# nrf7140_sysctrl register map
Vendor: Nordic Semiconductor; Series: nRF71; File version: 1
Registers are 32-bit, read-write, reset 0x0 unless marked. A register's access mark holds for its fields unless they carry their own. Offsets are from the block's base; [hi:lo] are bit positions; lines under a group give offsets from that group; 'fields as' and 'values as' point back to an identical list.

## VDETPOF5V0 — VDETPOF5V0 peripheral 0
Base 0x5F979000
Same registers: VDETPOFVBAT 0x5F97A000
0x00 TASKS_PWRUP wo — Power up voltage detector
  [0] TASKS_PWRUP
    1=Trigger task
0x04 TASKS_PWRDOWN wo — Power down voltage detector
  [0] TASKS_PWRDOWN
    1=Trigger task
0x100 EVENTS_READY — Power up done
  [0] EVENTS_READY
    0=NotGenerated (Event not generated); 1=Generated (Event generated)
0x104 EVENTS_SETTLED — Settled flag for MODE handshake
  [0] EVENTS_SETTLED
    values as EVENTS_READY.EVENTS_READY
0x108 EVENTS_POFWARN — Power failure warning
  [0] EVENTS_POFWARN
    values as EVENTS_READY.EVENTS_READY
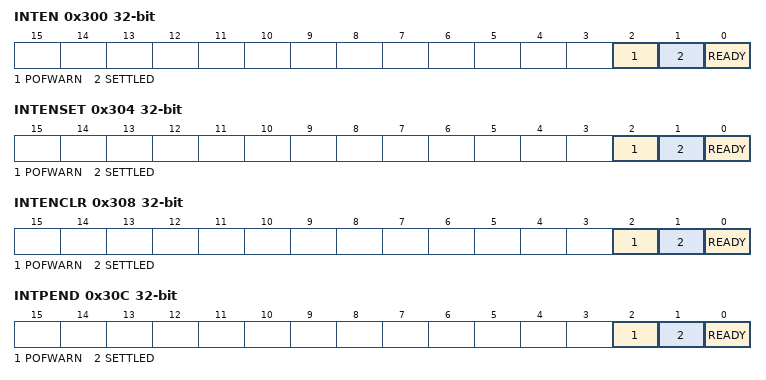
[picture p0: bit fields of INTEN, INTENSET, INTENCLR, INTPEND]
0x300 INTEN — Enable or disable interrupt
  [all] fields
    0=Disabled; 1=Enabled
  [2] POFWARN — Enable or disable interrupt for event POFWARN
  [1] SETTLED — Enable or disable interrupt for event SETTLED
  [0] READY — Enable or disable interrupt for event READY
0x304 INTENSET — Enable interrupt
  [all] fields
    on read: 0=Disabled (Read: Disabled); 1=Enabled (Read: Enabled) | on write: 1=Set (Enable)
  [2] POFWARN — Write '1' to enable interrupt for event POFWARN
  [1] SETTLED — Write '1' to enable interrupt for event SETTLED
  [0] READY — Write '1' to enable interrupt for event READY
0x308 INTENCLR — Disable interrupt
  [all] fields
    on read: 0=Disabled (Read: Disabled); 1=Enabled (Read: Enabled) | on write: 1=Clear (Disable)
  [2] POFWARN — Write '1' to disable interrupt for event POFWARN
  [1] SETTLED — Write '1' to disable interrupt for event SETTLED
  [0] READY — Write '1' to disable interrupt for event READY
0x30C INTPEND ro — Pending interrupts
  [all] fields
    on read: 0=NotPending (Read: Not pending); 1=Pending (Read: Pending)
  [2] POFWARN — Read pending status of interrupt for event POFWARN
  [1] SETTLED — Read pending status of interrupt for event SETTLED
  [0] READY — Read pending status of interrupt for event READY
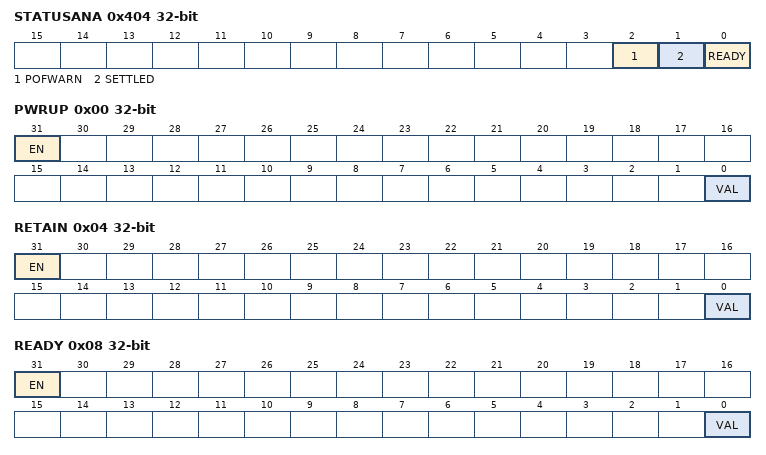
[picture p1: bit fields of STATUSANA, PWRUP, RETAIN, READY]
0x404 STATUSANA ro — Status of analog module output signals
  [2] POFWARN — Current value of the POFAO5V0_WARN signal from the analog module
  [1] SETTLED — Current value of the SETTLED signal from the analog module
  [0] READY — Current value of the READY signal from the analog module
0x410 CONFIG group — Unspecified
  0x00 CFG — Voltage detector configuration
    [1:0] POFWARNHYST — Power fail comparator hysteresis voltage value
      0=Val0V050 (Hysteresis voltage is 50mV); 1=Val0V100 (Hysteresis voltage is 100mV); 2=Val0V000 (Hysteresis voltage is 0mV); 3=Val0V025 (Hysteresis voltage is 25mV)
  0x04 POFWARNLVL — Power fail comparator threshold voltage level
    [4:0] VAL — Threshold voltage value.
0x440 TRIM group — Unspecified
  0x00 POFWARN — Power fail comparator trimming
    [2:0] VAL — Threshold voltage trimming value
0x480 MIRROR reset 0x1 — Enable LOCK for mirrored registers
  [0] LOCK — Lock for mirrored registers
    0=Disabled (Lock disabled); 1=Enabled (Lock enabled)
0x500 OVERRIDE group — Unspecified
  0x00 PWRUP — Override the PWRUP signal to the analog module
    [31] EN — Enable the override
      0=Disabled (Override is disabled); 1=Enabled (Override is enabled)
    [0] VAL — Override value for the signal
  0x04 RETAIN — Override the RETAIN signal to the analog module
    fields as OVERRIDE.PWRUP
  0x08 READY — Override the READY signal from the analog module
    [31] EN — Enable the override
      values as OVERRIDE.PWRUP.EN
    [0] VAL — Current value of the signal
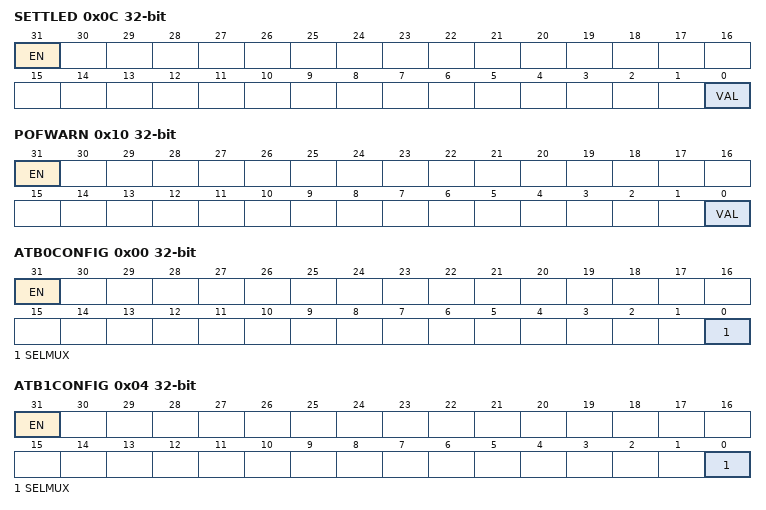
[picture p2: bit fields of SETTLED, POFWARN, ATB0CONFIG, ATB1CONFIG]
  0x0C SETTLED — Override the SETTLED signal from the analog module
    fields as OVERRIDE.READY
  0x10 POFWARN — Override the POFAO5V0_WARN signal from the analog module
    fields as OVERRIDE.READY
0x600 DFT group — Unspecified
  0x00 ATB0CONFIG — Analog Test Bus 0 (ATB0) configuration
    [31] EN — Enable the analog test bus
      0=Disabled (Analog test bus is disabled); 1=Enabled (Analog test bus is enabled)
    [0] SELMUX — Select multiplexer for ATB0
      0=ATB0sense (Use ATB0 voltage for sensing instead of VDIV tap voltage); 1=Connect VSS to ATB0
  0x04 ATB1CONFIG — Analog Test Bus 1 (ATB1) configuration
    [31] EN — Enable the analog test bus
      values as DFT.ATB0CONFIG.EN
    [0] SELMUX — Select multiplexer for ATB1
      0=Connect VREF to ATB1; 1=Connect VDIV to ATB1
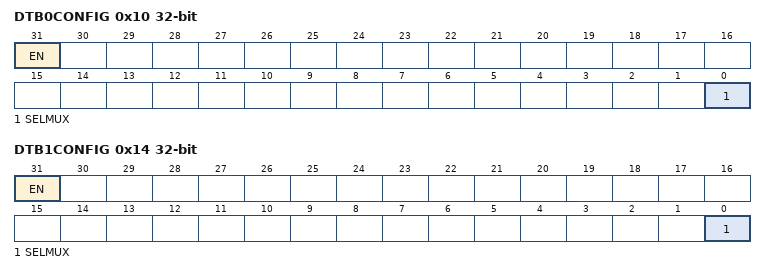
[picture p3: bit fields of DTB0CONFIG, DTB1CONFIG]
  0x10 DTB0CONFIG — Digital Test Bus 0 (DTB0) configuration
    [31] EN — Enable the digital test bus
      0=Disabled (Digital test bus is disabled); 1=Enabled (Digital test bus is enabled)
    [0] SELMUX — Select multiplexer for DTB0
      0=READY_POFAO5V0_AO_0V8; 1=PofWarn (POFAO5V0_WARN_AO_0V8)
  0x14 DTB1CONFIG — Digital Test Bus 1 (DTB1) configuration
    [31] EN — Enable the digital test bus
      values as DFT.DTB0CONFIG.EN
    [0] SELMUX — Select multiplexer for DTB1
      0=ReadyCmp (POFAO5V0_READY_CMP_2DTB_0V8 (from READY_CMP_SW_1V8)); 1=SETTLED_POFAO5V0_AO_0V8
  0x1C DTB3CONFIG — Digital Test Bus 3 (DTB3) configuration
    [27] PWRUPDELTEST — Enable the PWRUP delay test circuit
      0=Disabled (PWRUP delay test circuit is disabled); 1=Enabled (PWRUP delay test circuit is enabled)
